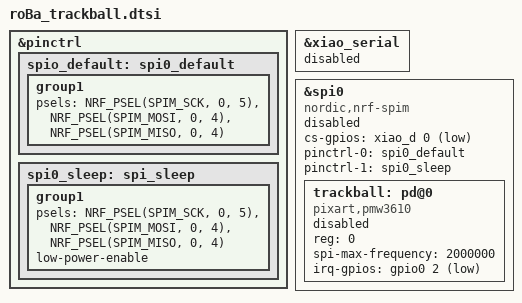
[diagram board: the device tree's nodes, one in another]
/*
 * Copyright (c) 2020 Pete Johanson
 *
 * SPDX-License-Identifier: MIT
 */
#include <zephyr/dt-bindings/input/input-event-codes.h>


&pinctrl {
    spio_default: spi0_default {
        group1 {
            psels = <NRF_PSEL(SPIM_SCK, 0, 5)>,
                <NRF_PSEL(SPIM_MOSI, 0, 4)>,
                <NRF_PSEL(SPIM_MISO, 0, 4)>;
        };
    };

    spi0_sleep: spi_sleep {
        group1 {
            psels = <NRF_PSEL(SPIM_SCK, 0, 5)>,
                <NRF_PSEL(SPIM_MOSI, 0, 4)>,
                <NRF_PSEL(SPIM_MISO, 0, 4)>;
            low-power-enable;
        };
    };
};


&xiao_serial { status = "disabled"; };



&spi0 {
    status = "disabled";
    cs-gpios =  <&xiao_d 0 GPIO_ACTIVE_LOW>;
    pinctrl-0 = <&spi0_default>;
    pinctrl-1 = <&spi0_sleep>;
    pinctrl-names = "default", "sleep";
    compatible = "nordic,nrf-spim";

    trackball: pd@0 {
        status = "disabled";
        compatible = "pixart,pmw3610";
        reg = <0>;
        spi-max-frequency = <2000000>;
        irq-gpios = <&gpio0 2 (GPIO_ACTIVE_LOW | GPIO_PULL_UP)>;
    };
};



